# Espressif register map
File version: 1.0
CPU: Xtensa LX6 1, little endian, no MPU, FPU, 3 interrupt priority bits
Registers are 32-bit, access not given, reset 0x0 unless marked. A register's access mark holds for its fields unless they carry their own. Offsets are from the block's base; [hi:lo] are bit positions.

## I2S
Base 0x3FF4F000
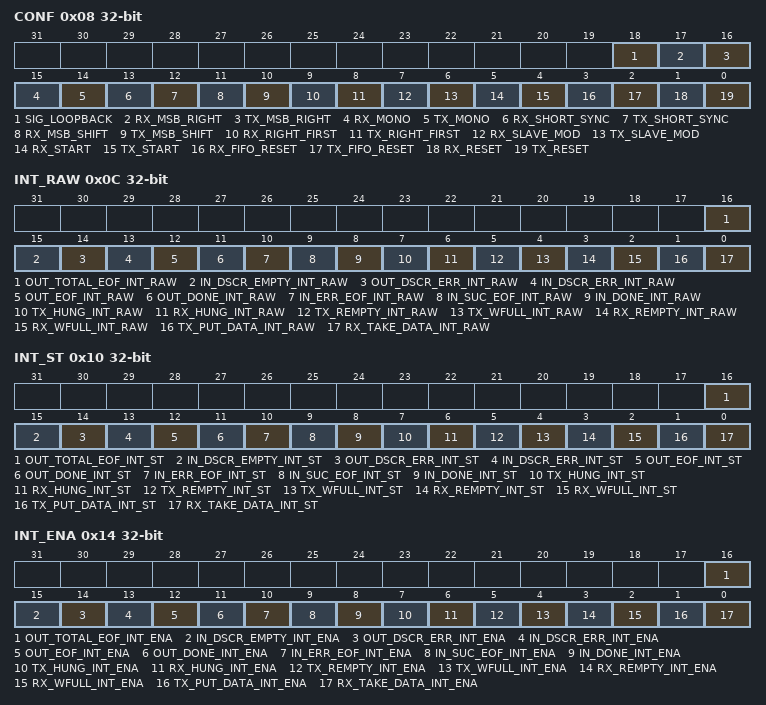
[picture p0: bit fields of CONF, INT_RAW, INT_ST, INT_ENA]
0x08 CONF — I2S_CONF
  [18] SIG_LOOPBACK, [17] RX_MSB_RIGHT, [16] TX_MSB_RIGHT, [15] RX_MONO, [14] TX_MONO, [13] RX_SHORT_SYNC, [12] TX_SHORT_SYNC, [11] RX_MSB_SHIFT, [10] TX_MSB_SHIFT, [9] RX_RIGHT_FIRST, [8] TX_RIGHT_FIRST, [7] RX_SLAVE_MOD, [6] TX_SLAVE_MOD, [5] RX_START, [4] TX_START, [3] RX_FIFO_RESET, [2] TX_FIFO_RESET, [1] RX_RESET, [0] TX_RESET
0x0C INT_RAW — I2S_INT_RAW
  [16] OUT_TOTAL_EOF_INT_RAW, [15] IN_DSCR_EMPTY_INT_RAW, [14] OUT_DSCR_ERR_INT_RAW, [13] IN_DSCR_ERR_INT_RAW, [12] OUT_EOF_INT_RAW, [11] OUT_DONE_INT_RAW, [10] IN_ERR_EOF_INT_RAW, [9] IN_SUC_EOF_INT_RAW, [8] IN_DONE_INT_RAW, [7] TX_HUNG_INT_RAW, [6] RX_HUNG_INT_RAW, [5] TX_REMPTY_INT_RAW, [4] TX_WFULL_INT_RAW, [3] RX_REMPTY_INT_RAW, [2] RX_WFULL_INT_RAW, [1] TX_PUT_DATA_INT_RAW, [0] RX_TAKE_DATA_INT_RAW
0x10 INT_ST — I2S_INT_ST
  [16] OUT_TOTAL_EOF_INT_ST, [15] IN_DSCR_EMPTY_INT_ST, [14] OUT_DSCR_ERR_INT_ST, [13] IN_DSCR_ERR_INT_ST, [12] OUT_EOF_INT_ST, [11] OUT_DONE_INT_ST, [10] IN_ERR_EOF_INT_ST, [9] IN_SUC_EOF_INT_ST, [8] IN_DONE_INT_ST, [7] TX_HUNG_INT_ST, [6] RX_HUNG_INT_ST, [5] TX_REMPTY_INT_ST, [4] TX_WFULL_INT_ST, [3] RX_REMPTY_INT_ST, [2] RX_WFULL_INT_ST, [1] TX_PUT_DATA_INT_ST, [0] RX_TAKE_DATA_INT_ST
0x14 INT_ENA — I2S_INT_ENA
  [16] OUT_TOTAL_EOF_INT_ENA, [15] IN_DSCR_EMPTY_INT_ENA, [14] OUT_DSCR_ERR_INT_ENA, [13] IN_DSCR_ERR_INT_ENA, [12] OUT_EOF_INT_ENA, [11] OUT_DONE_INT_ENA, [10] IN_ERR_EOF_INT_ENA, [9] IN_SUC_EOF_INT_ENA, [8] IN_DONE_INT_ENA, [7] TX_HUNG_INT_ENA, [6] RX_HUNG_INT_ENA, [5] TX_REMPTY_INT_ENA, [4] TX_WFULL_INT_ENA, [3] RX_REMPTY_INT_ENA, [2] RX_WFULL_INT_ENA, [1] TX_PUT_DATA_INT_ENA, [0] RX_TAKE_DATA_INT_ENA
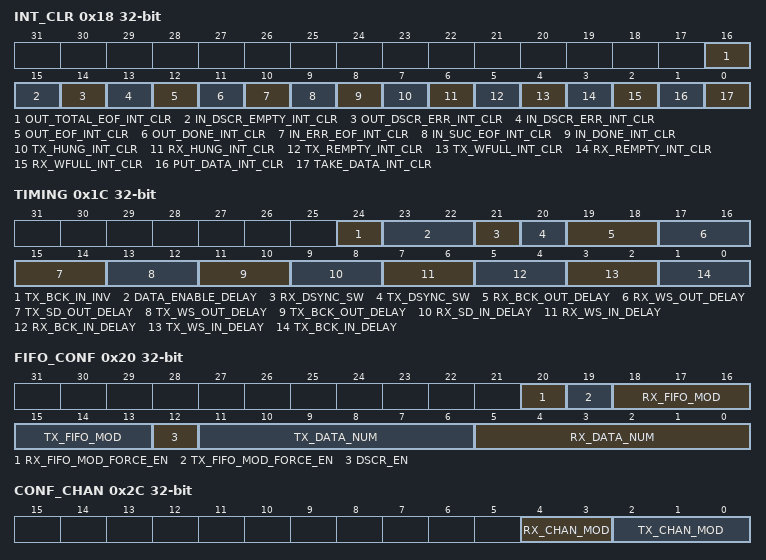
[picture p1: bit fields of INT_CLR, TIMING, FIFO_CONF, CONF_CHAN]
0x18 INT_CLR — I2S_INT_CLR
  [16] OUT_TOTAL_EOF_INT_CLR, [15] IN_DSCR_EMPTY_INT_CLR, [14] OUT_DSCR_ERR_INT_CLR, [13] IN_DSCR_ERR_INT_CLR, [12] OUT_EOF_INT_CLR, [11] OUT_DONE_INT_CLR, [10] IN_ERR_EOF_INT_CLR, [9] IN_SUC_EOF_INT_CLR, [8] IN_DONE_INT_CLR, [7] TX_HUNG_INT_CLR, [6] RX_HUNG_INT_CLR, [5] TX_REMPTY_INT_CLR, [4] TX_WFULL_INT_CLR, [3] RX_REMPTY_INT_CLR, [2] RX_WFULL_INT_CLR, [1] PUT_DATA_INT_CLR, [0] TAKE_DATA_INT_CLR
0x1C TIMING — I2S_TIMING
  [24] TX_BCK_IN_INV, [23:22] DATA_ENABLE_DELAY, [21] RX_DSYNC_SW, [20] TX_DSYNC_SW, [19:18] RX_BCK_OUT_DELAY, [17:16] RX_WS_OUT_DELAY, [15:14] TX_SD_OUT_DELAY, [13:12] TX_WS_OUT_DELAY, [11:10] TX_BCK_OUT_DELAY, [9:8] RX_SD_IN_DELAY, [7:6] RX_WS_IN_DELAY, [5:4] RX_BCK_IN_DELAY, [3:2] TX_WS_IN_DELAY, [1:0] TX_BCK_IN_DELAY
0x20 FIFO_CONF — I2S_FIFO_CONF
  [20] RX_FIFO_MOD_FORCE_EN, [19] TX_FIFO_MOD_FORCE_EN, [18:16] RX_FIFO_MOD, [15:13] TX_FIFO_MOD, [12] DSCR_EN, [11:6] TX_DATA_NUM, [5:0] RX_DATA_NUM
0x24 RXEOF_NUM — I2S_RXEOF_NUM
  [31:0] RX_EOF_NUM
0x28 CONF_SIGLE_DATA — I2S_CONF_SIGLE_DATA
  [31:0] SIGLE_DATA
0x2C CONF_CHAN — I2S_CONF_CHAN
  [4:3] RX_CHAN_MOD, [2:0] TX_CHAN_MOD
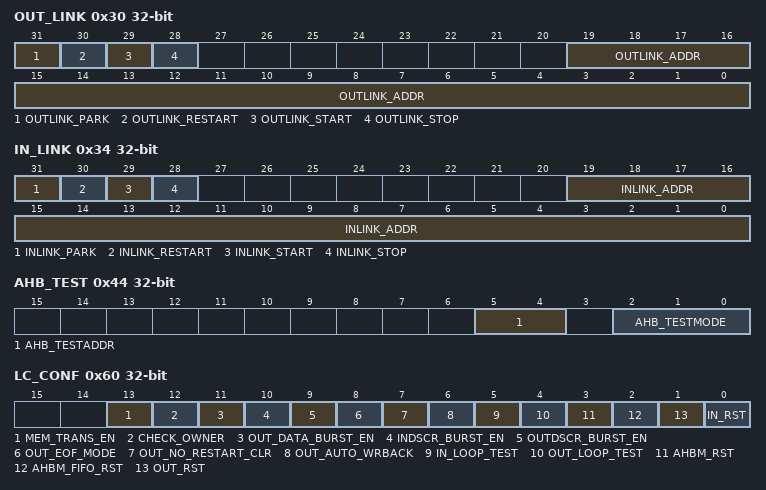
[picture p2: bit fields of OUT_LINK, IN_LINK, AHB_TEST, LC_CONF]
0x30 OUT_LINK — I2S_OUT_LINK
  [31] OUTLINK_PARK, [30] OUTLINK_RESTART, [29] OUTLINK_START, [28] OUTLINK_STOP, [19:0] OUTLINK_ADDR
0x34 IN_LINK — I2S_IN_LINK
  [31] INLINK_PARK, [30] INLINK_RESTART, [29] INLINK_START, [28] INLINK_STOP, [19:0] INLINK_ADDR
0x38 OUT_EOF_DES_ADDR — I2S_OUT_EOF_DES_ADDR
0x3C IN_EOF_DES_ADDR — I2S_IN_EOF_DES_ADDR
  [31:0] IN_SUC_EOF_DES_ADDR
0x40 OUT_EOF_BFR_DES_ADDR — I2S_OUT_EOF_BFR_DES_ADDR
0x44 AHB_TEST — I2S_AHB_TEST
  [5:4] AHB_TESTADDR, [2:0] AHB_TESTMODE
0x48 INLINK_DSCR — I2S_INLINK_DSCR
0x4C INLINK_DSCR_BF0 — I2S_INLINK_DSCR_BF0
0x50 INLINK_DSCR_BF1 — I2S_INLINK_DSCR_BF1
0x54 OUTLINK_DSCR — I2S_OUTLINK_DSCR
0x58 OUTLINK_DSCR_BF0 — I2S_OUTLINK_DSCR_BF0
0x5C OUTLINK_DSCR_BF1 — I2S_OUTLINK_DSCR_BF1
0x60 LC_CONF — I2S_LC_CONF
  [13] MEM_TRANS_EN, [12] CHECK_OWNER, [11] OUT_DATA_BURST_EN, [10] INDSCR_BURST_EN, [9] OUTDSCR_BURST_EN, [8] OUT_EOF_MODE, [7] OUT_NO_RESTART_CLR, [6] OUT_AUTO_WRBACK, [5] IN_LOOP_TEST, [4] OUT_LOOP_TEST, [3] AHBM_RST, [2] AHBM_FIFO_RST, [1] OUT_RST, [0] IN_RST
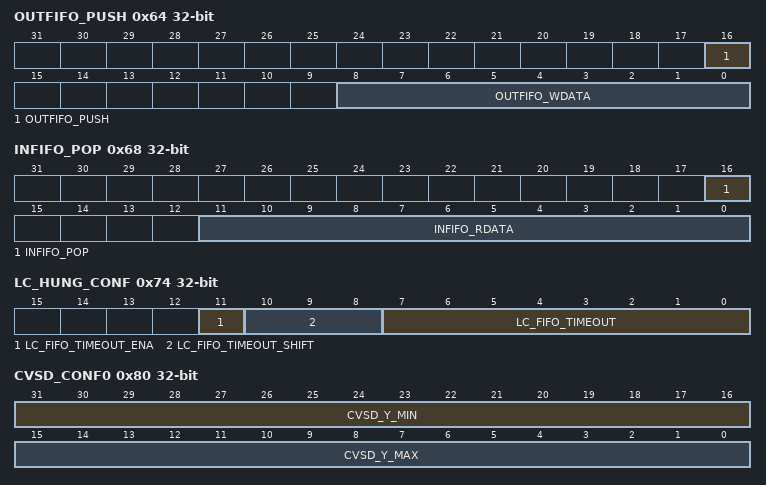
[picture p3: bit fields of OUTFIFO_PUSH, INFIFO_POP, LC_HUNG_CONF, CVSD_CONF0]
0x64 OUTFIFO_PUSH — I2S_OUTFIFO_PUSH
  [16] OUTFIFO_PUSH, [8:0] OUTFIFO_WDATA
0x68 INFIFO_POP — I2S_INFIFO_POP
  [16] INFIFO_POP, [11:0] INFIFO_RDATA
0x6C LC_STATE0 — I2S_LC_STATE0
0x70 LC_STATE1 — I2S_LC_STATE1
0x74 LC_HUNG_CONF — I2S_LC_HUNG_CONF
  [11] LC_FIFO_TIMEOUT_ENA, [10:8] LC_FIFO_TIMEOUT_SHIFT, [7:0] LC_FIFO_TIMEOUT
0x80 CVSD_CONF0 — I2S_CVSD_CONF0
  [31:16] CVSD_Y_MIN, [15:0] CVSD_Y_MAX
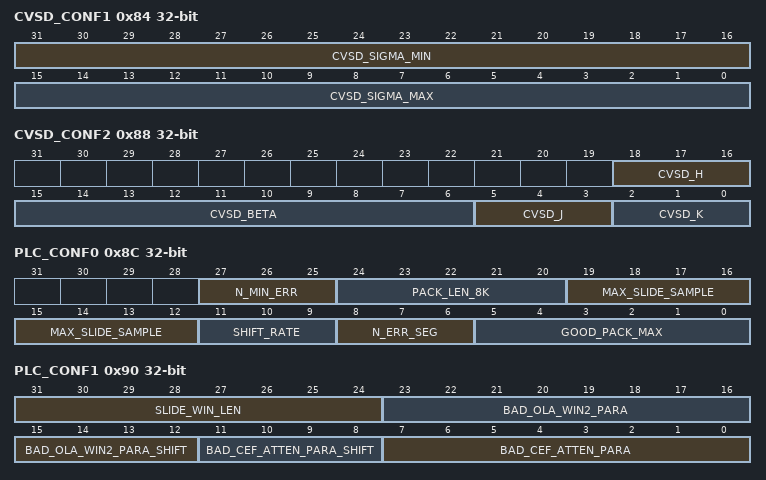
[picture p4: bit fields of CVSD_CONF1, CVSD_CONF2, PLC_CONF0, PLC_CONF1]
0x84 CVSD_CONF1 — I2S_CVSD_CONF1
  [31:16] CVSD_SIGMA_MIN, [15:0] CVSD_SIGMA_MAX
0x88 CVSD_CONF2 — I2S_CVSD_CONF2
  [18:16] CVSD_H, [15:6] CVSD_BETA, [5:3] CVSD_J, [2:0] CVSD_K
0x8C PLC_CONF0 — I2S_PLC_CONF0
  [27:25] N_MIN_ERR, [24:20] PACK_LEN_8K, [19:12] MAX_SLIDE_SAMPLE, [11:9] SHIFT_RATE, [8:6] N_ERR_SEG, [5:0] GOOD_PACK_MAX
0x90 PLC_CONF1 — I2S_PLC_CONF1
  [31:24] SLIDE_WIN_LEN, [23:16] BAD_OLA_WIN2_PARA, [15:12] BAD_OLA_WIN2_PARA_SHIFT, [11:8] BAD_CEF_ATTEN_PARA_SHIFT, [7:0] BAD_CEF_ATTEN_PARA
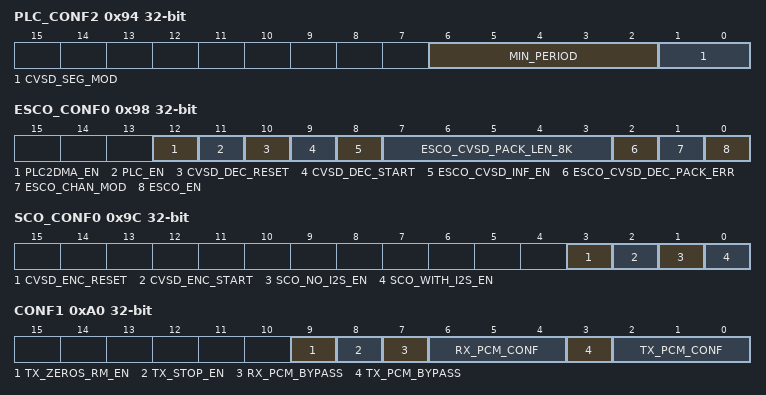
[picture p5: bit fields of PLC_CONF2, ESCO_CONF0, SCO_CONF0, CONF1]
0x94 PLC_CONF2 — I2S_PLC_CONF2
  [6:2] MIN_PERIOD, [1:0] CVSD_SEG_MOD
0x98 ESCO_CONF0 — I2S_ESCO_CONF0
  [12] PLC2DMA_EN, [11] PLC_EN, [10] CVSD_DEC_RESET, [9] CVSD_DEC_START, [8] ESCO_CVSD_INF_EN, [7:3] ESCO_CVSD_PACK_LEN_8K, [2] ESCO_CVSD_DEC_PACK_ERR, [1] ESCO_CHAN_MOD, [0] ESCO_EN
0x9C SCO_CONF0 — I2S_SCO_CONF0
  [3] CVSD_ENC_RESET, [2] CVSD_ENC_START, [1] SCO_NO_I2S_EN, [0] SCO_WITH_I2S_EN
0xA0 CONF1 — I2S_CONF1
  [9] TX_ZEROS_RM_EN, [8] TX_STOP_EN, [7] RX_PCM_BYPASS, [6:4] RX_PCM_CONF, [3] TX_PCM_BYPASS, [2:0] TX_PCM_CONF
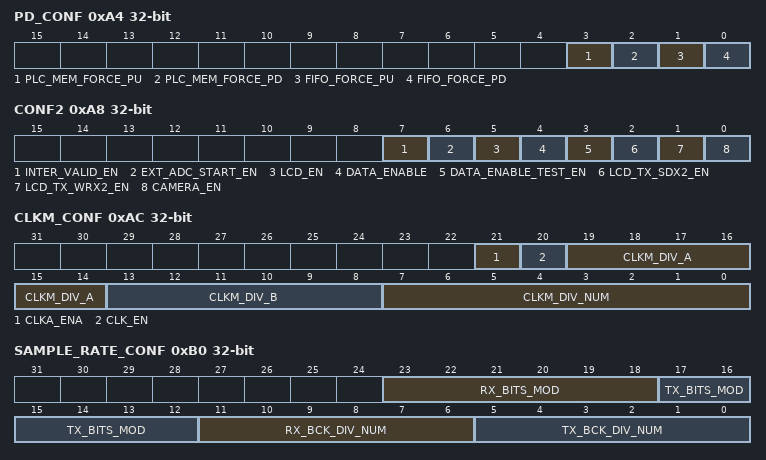
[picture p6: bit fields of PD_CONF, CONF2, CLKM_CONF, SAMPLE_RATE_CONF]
0xA4 PD_CONF — I2S_PD_CONF
  [3] PLC_MEM_FORCE_PU, [2] PLC_MEM_FORCE_PD, [1] FIFO_FORCE_PU, [0] FIFO_FORCE_PD
0xA8 CONF2 — I2S_CONF2
  [7] INTER_VALID_EN, [6] EXT_ADC_START_EN, [5] LCD_EN, [4] DATA_ENABLE, [3] DATA_ENABLE_TEST_EN, [2] LCD_TX_SDX2_EN, [1] LCD_TX_WRX2_EN, [0] CAMERA_EN
0xAC CLKM_CONF — I2S_CLKM_CONF
  [21] CLKA_ENA, [20] CLK_EN, [19:14] CLKM_DIV_A, [13:8] CLKM_DIV_B, [7:0] CLKM_DIV_NUM
0xB0 SAMPLE_RATE_CONF — I2S_SAMPLE_RATE_CONF
  [23:18] RX_BITS_MOD, [17:12] TX_BITS_MOD, [11:6] RX_BCK_DIV_NUM, [5:0] TX_BCK_DIV_NUM
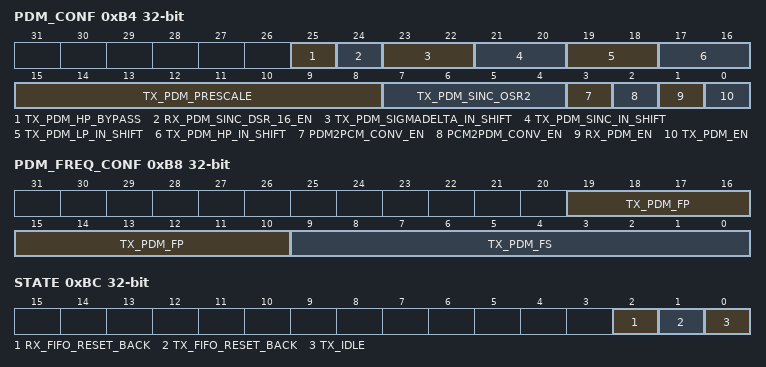
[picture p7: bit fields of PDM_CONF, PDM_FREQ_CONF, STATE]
0xB4 PDM_CONF — I2S_PDM_CONF
  [25] TX_PDM_HP_BYPASS, [24] RX_PDM_SINC_DSR_16_EN, [23:22] TX_PDM_SIGMADELTA_IN_SHIFT, [21:20] TX_PDM_SINC_IN_SHIFT, [19:18] TX_PDM_LP_IN_SHIFT, [17:16] TX_PDM_HP_IN_SHIFT, [15:8] TX_PDM_PRESCALE, [7:4] TX_PDM_SINC_OSR2, [3] PDM2PCM_CONV_EN, [2] PCM2PDM_CONV_EN, [1] RX_PDM_EN, [0] TX_PDM_EN
0xB8 PDM_FREQ_CONF — I2S_PDM_FREQ_CONF
  [19:10] TX_PDM_FP, [9:0] TX_PDM_FS
0xBC STATE — I2S_STATE
  [2] RX_FIFO_RESET_BACK, [1] TX_FIFO_RESET_BACK, [0] TX_IDLE
0xFC DATE — I2S_DATE
  [31:0] I2SDATE
